VERSION "$Format:%h$"

NS_ :

BS_:

BU_: LOGGER SAMPLE

BO_ 256 SAMPLE_A_alertLog: 8 SAMPLE_A
 SG_ SAMPLE_A_alertID M : 0|7@1+ (1,0) [0|76] "" LOGGER
 SG_ SAMPLE_A_alertState : 15|1@1+ (1,0) [0|1] "" LOGGER
 SG_ SAMPLE_A_a005_data1 m5 : 16|1@1+ (1,0) [0|1] "" LOGGER
 SG_ SAMPLE_A_a005_data2 m5 : 17|1@1+ (1,0) [0|1] "" LOGGER
 SG_ SAMPLE_A_a006_data1 m6 : 16|16@1+ (1,0) [0|65535] "" LOGGER
 SG_ SAMPLE_A_a006_data2 m6 : 32|16@1+ (1,0) [0|65535] "" LOGGER
 SG_ SAMPLE_A_a008_data1 m8 : 16|16@1+ (1,0) [0|65535] "" LOGGER
 SG_ SAMPLE_A_a008_data2 m8 : 32|8@1+ (1,0) [0|255] "" LOGGER
 SG_ SAMPLE_A_a008_data3 m8 : 40|8@1+ (1,0) [0|255] "" LOGGER
 SG_ SAMPLE_A_a008_data4 m8 : 48|1@1+ (1,0) [0|1] "" LOGGER
 SG_ SAMPLE_A_a008_data5 m8 : 49|1@1+ (1,0) [0|1] "" LOGGER
 SG_ SAMPLE_A_a009_data1 m9 : 16|16@1+ (1,0) [0|65535] "" LOGGER
 SG_ SAMPLE_A_a009_data2 m9 : 32|8@1+ (1,0) [0|255] "" LOGGER
 SG_ SAMPLE_A_a009_data3 m9 : 40|8@1+ (1,0) [0|255] "" LOGGER
 SG_ SAMPLE_A_a009_data4 m9 : 48|1@1+ (1,0) [0|1] "" LOGGER
 SG_ SAMPLE_A_a009_data5 m9 : 49|1@1+ (1,0) [0|1] "" LOGGER
 SG_ SAMPLE_A_a020_data1 m20 : 16|7@1+ (1,1) [1|128] "" LOGGER
 SG_ SAMPLE_A_a020_data2 m20 : 24|8@1+ (0.5,0) [0|100] "PCT" LOGGER
 SG_ SAMPLE_A_a020_data3 m20 : 32|7@1+ (1,1) [1|128] "" LOGGER
 SG_ SAMPLE_A_a020_data4 m20 : 40|8@1+ (0.5,0) [0|100] "PCT" LOGGER
 SG_ SAMPLE_A_a020_data5 m20 : 48|8@1+ (0.5,0) [0|100] "PCT" LOGGER
 SG_ SAMPLE_A_a021_data1 m21 : 16|7@1+ (1,1) [1|128] "" LOGGER
 SG_ SAMPLE_A_a021_data2 m21 : 24|8@1+ (0.5,0) [0|100] "PCT" LOGGER
 SG_ SAMPLE_A_a021_data3 m21 : 32|7@1+ (1,1) [1|128] "" LOGGER
 SG_ SAMPLE_A_a021_data4 m21 : 40|8@1+ (0.5,0) [0|100] "PCT" LOGGER
 SG_ SAMPLE_A_a021_data5 m21 : 48|7@1+ (1,0) [0|100] "PCT" LOGGER
 SG_ SAMPLE_A_a021_data6 m21 : 56|7@1+ (1,0) [0|100] "PCT" LOGGER

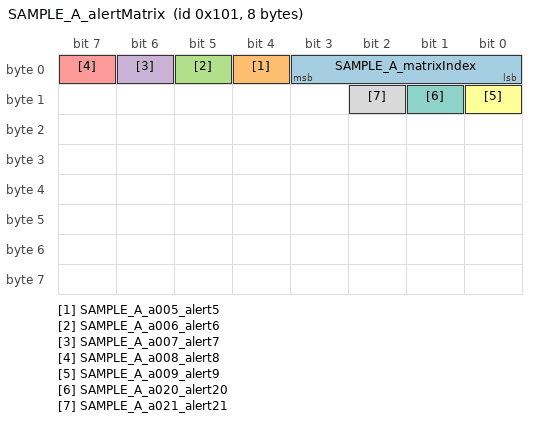
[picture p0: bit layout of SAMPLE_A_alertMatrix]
BO_ 257 SAMPLE_A_alertMatrix: 8 SAMPLE_A
 SG_ SAMPLE_A_matrixIndex : 0|4@1+ (1,0) [0|15] "" Vector__XXX
 SG_ SAMPLE_A_a005_alert5 : 4|1@1+ (1,0) [0|1] "" LOGGER
 SG_ SAMPLE_A_a006_alert6 : 5|1@1+ (1,0) [0|1] "" LOGGER
 SG_ SAMPLE_A_a007_alert7 : 6|1@1+ (1,0) [0|1] "" LOGGER
 SG_ SAMPLE_A_a008_alert8 : 7|1@1+ (1,0) [0|1] "" LOGGER
 SG_ SAMPLE_A_a009_alert9 : 8|1@1+ (1,0) [0|1] "" LOGGER
 SG_ SAMPLE_A_a020_alert20 : 9|1@1+ (1,0) [0|1] "" LOGGER
 SG_ SAMPLE_A_a021_alert21 : 10|1@1+ (1,0) [0|1] "" LOGGER

BO_ 1792 SAMPLE_B_debug: 8 SAMPLE_B
 SG_ SAMPLE_B_debugMultiplexer M : 0|8@1+ (1,0) [0|9] "" Vector__XXX
 SG_ SAMPLE_B_m0_data1 m0 : 8|10@1+ (0.1,0) [0|100] "%" Vector__XXX
 SG_ SAMPLE_B_m0_data2 m0 : 18|10@1+ (0.1,0) [0|100] "%" Vector__XXX
 SG_ SAMPLE_B_m0_data3 m0 : 28|10@1+ (0.1,0) [0|100] "%" Vector__XXX
 SG_ SAMPLE_B_m0_data4 m0 : 38|10@1+ (0.002,0) [0|2] "A" Vector__XXX
 SG_ SAMPLE_B_m0_data5 m0 : 48|6@1+ (0.025,0) [0|1.55] "A" Vector__XXX
 SG_ SAMPLE_B_m0_data6 m0 : 54|1@1+ (1,0) [0|1] "" Vector__XXX
 SG_ SAMPLE_B_m0_data7 m0 : 55|1@1+ (1,0) [0|1] "" Vector__XXX
 SG_ SAMPLE_B_m0_data8 m0 : 56|1@1+ (1,0) [0|1] "" Vector__XXX
 SG_ SAMPLE_B_m0_data9 m0 : 57|1@1+ (1,0) [0|1] "" Vector__XXX
 SG_ SAMPLE_B_m0_data10 m0 : 58|1@1+ (1,0) [0|1] "" Vector__XXX
 SG_ SAMPLE_B_m0_data11 m0 : 59|1@1+ (1,0) [0|1] "" Vector__XXX
 SG_ SAMPLE_B_m0_data12 m0 : 60|1@1+ (1,0) [0|1] "" Vector__XXX
 SG_ SAMPLE_B_m0_data13 m0 : 61|1@1+ (1,0) [0|1] "" Vector__XXX
 SG_ SAMPLE_B_m0_data14 m0 : 62|1@1+ (1,0) [0|1] "" Vector__XXX
 SG_ SAMPLE_B_m1_data1 m1 : 8|12@1+ (0.005,0) [0|20.47] "Ah" Vector__XXX
 SG_ SAMPLE_B_m1_data2 m1 : 20|12@1+ (0.005,0) [0|20.47] "Ah" Vector__XXX
 SG_ SAMPLE_B_m1_data3 m1 : 32|5@1+ (1,1) [1|31] "" Vector__XXX
 SG_ SAMPLE_B_m1_data4 m1 : 40|5@1+ (1,1) [1|31] "" Vector__XXX
 SG_ SAMPLE_B_m1_data5 m1 : 48|12@1+ (0.02,0) [0|81.88] "V" Vector__XXX
 SG_ SAMPLE_B_m2_data1 m2 : 8|11@1+ (0.1,-50) [-50|154.6] "C" Vector__XXX
 SG_ SAMPLE_B_m2_data2 m2 : 19|11@1+ (0.1,-50) [-50|154.6] "C" Vector__XXX
 SG_ SAMPLE_B_m2_data3 m2 : 30|11@1+ (0.1,-50) [-50|154.6] "C" Vector__XXX
 SG_ SAMPLE_B_m2_data4 m2 : 41|11@1+ (0.1,-50) [-50|154.6] "C" Vector__XXX
 SG_ SAMPLE_B_m2_data5 m2 : 52|12@1+ (0.002,0) [0|8.188] "V" Vector__XXX
 SG_ SAMPLE_B_m3_data1 m3 : 8|5@1+ (1,0) [0|18] "" Vector__XXX
 SG_ SAMPLE_B_m3_data2 m3 : 16|4@1+ (1,0) [0|15] "" Vector__XXX
 SG_ SAMPLE_B_m3_data3 m3 : 20|7@1+ (0.1,90) [90|100] "%" Vector__XXX
 SG_ SAMPLE_B_m3_data4 m3 : 27|10@1+ (0.1,0) [0|80] "%" Vector__XXX
 SG_ SAMPLE_B_m3_data5 m3 : 37|7@1+ (0.2,-0.2) [-0.2|25] "Ah" Vector__XXX
 SG_ SAMPLE_B_m3_data6 m3 : 44|10@1+ (0.2,-0.2) [-0.2|204.2] "Wh" Vector__XXX
 SG_ SAMPLE_B_m3_data7 m3 : 54|10@1+ (0.1,-0.1) [-0.1|102.1] "min" Vector__XXX
 SG_ SAMPLE_B_m4_data1 m4 : 8|12@1+ (0.015,0) [0|61.41] "V" Vector__XXX
 SG_ SAMPLE_B_m4_data2 m4 : 20|10@1+ (0.1,0) [0|100] "%" Vector__XXX
 SG_ SAMPLE_B_m4_data3 m4 : 30|10@1+ (0.1,0) [0|100] "%" Vector__XXX
 SG_ SAMPLE_B_m4_data4 m4 : 40|10@1+ (0.1,0) [0|100] "%" Vector__XXX
 SG_ SAMPLE_B_m4_data5 m4 : 50|12@1- (0.25,0) [-511|511] "A" Vector__XXX
 SG_ SAMPLE_B_m5_data1 m5 : 8|14@1+ (2.5e-5,0) [0|0.4] "Ohm" Vector__XXX
 SG_ SAMPLE_B_m5_data2 m5 : 24|14@1+ (2.5e-5,0) [0|0.4] "Ohm" Vector__XXX
 SG_ SAMPLE_B_m5_data3 m5 : 40|14@1+ (2.5e-5,0) [0|0.4] "Ohm" Vector__XXX
 SG_ SAMPLE_B_m5_data4 m5 : 54|5@1+ (1,1) [1|31] "" Vector__XXX
 SG_ SAMPLE_B_m5_data5 m5 : 59|5@1+ (1,1) [1|31] "" Vector__XXX
 SG_ SAMPLE_B_m6_data1 m6 : 8|12@1+ (2,-8000) [-8000|0] "W" Vector__XXX
 SG_ SAMPLE_B_m6_data2 m6 : 20|12@1+ (2,0) [0|8000] "W" Vector__XXX
 SG_ SAMPLE_B_m6_data3 m6 : 32|10@1+ (0.005,0) [0|5.115] "V" Vector__XXX
 SG_ SAMPLE_B_m6_data4 m6 : 42|10@1+ (0.005,0) [0|5.115] "V" Vector__XXX
 SG_ SAMPLE_B_m6_data5 m6 : 52|12@1+ (1,0) [0|4000] "Wh" Vector__XXX
 SG_ SAMPLE_B_m7_data1 m7 : 8|32@1+ (1,0) [0|4294967295] "s" Vector__XXX
 SG_ SAMPLE_B_m7_data2 m7 : 40|8@1+ (0.01,0.5) [0.5|3.04] "ratio" Vector__XXX
 SG_ SAMPLE_B_m7_data3 m7 : 48|5@1+ (1,1) [1|31] "" Vector__XXX
 SG_ SAMPLE_B_m7_data4 m7 : 56|4@1+ (1,0) [0|15] "" Vector__XXX
 SG_ SAMPLE_B_m8_data1 m8 : 8|13@1+ (864000,0) [0|7077024000] "s" Vector__XXX
 SG_ SAMPLE_B_m8_data2 m8 : 21|9@1+ (0.1,0) [0|51] "%" Vector__XXX
 SG_ SAMPLE_B_m8_data3 m8 : 32|14@1- (0.1,200) [-100|500] "%" Vector__XXX
 SG_ SAMPLE_B_m8_data4 m8 : 46|10@1+ (0.1,0) [0|102.2] "%" Vector__XXX
 SG_ SAMPLE_B_m8_data5 m8 : 56|3@1+ (1,0) [0|4] "" Vector__XXX
 SG_ SAMPLE_B_m9_data1 m9 : 8|8@1+ (0.01,0.5) [0.5|3.04] "ratio" Vector__XXX
 SG_ SAMPLE_B_m9_data2 m9 : 16|8@1+ (0.01,0.5) [0.5|3.04] "ratio" Vector__XXX
 SG_ SAMPLE_B_m9_data3 m9 : 24|12@1- (0.25,0) [-511|511] "A" Vector__XXX
 SG_ SAMPLE_B_m9_data4 m9 : 40|5@1+ (1,1) [1|31] "" Vector__XXX
 SG_ SAMPLE_B_m9_data5 m9 : 48|5@1+ (1,1) [1|31] "" Vector__XXX

BA_DEF_ "Baudrate" INT 0 1000000;
BA_DEF_ "BusID" INT 0 255;
BA_DEF_ "BusType" STRING ;
BA_DEF_ "DBName" STRING ;
BA_DEF_ "NetworkName" STRING ;
BA_DEF_ "NmBaseAddress" HEX 1024 1087;
BA_DEF_ BO_ "GatewayMessageSendType" ENUM "UseGenMsgSendType","onWrite","noAutoCode";
BA_DEF_ BO_ "GenMsgCycleTime" INT 0 0;
BA_DEF_ BO_ "GenMsgILSupport" ENUM "No","Yes";
BA_DEF_ BO_ "GenMsgSendType" ENUM "Cyclic","NotUsed","NotUsed","NotUsed","NotUsed","NotUsed","NotUsed","IfActive","NoMsgSendType","Sporadic";
BA_DEF_ BO_ "MessageIdType" ENUM "normal","udsRequest","udsResponse","udsReserved","udsFunctionalRequest","networkManagement","bootloader","xcp","dtc","diagnostic","vendorExempt";
BA_DEF_ BU_ "NodeLayerModules" STRING ;
BA_DEF_ SG_ "GenSigSendType" ENUM "Cyclic","OnWrite","OnWriteWithRepetition","OnChange","OnChangeWithRepetition","IfActive","IfActiveWithRepetition","NoSigSendType";
BA_DEF_ SG_ "GenSigStartValue" INT 0 0;

BA_DEF_DEF_ "Baudrate" 500000;
BA_DEF_DEF_ "BusID" 0;
BA_DEF_DEF_ "BusType" "CAN";
BA_DEF_DEF_ "DBName" "";
BA_DEF_DEF_ "GatewayMessageSendType" "UseGenMsgSendType";
BA_DEF_DEF_ "GenMsgCycleTime" 0;
BA_DEF_DEF_ "GenMsgILSupport" "Yes";
BA_DEF_DEF_ "GenMsgSendType" "NoMsgSendType";
BA_DEF_DEF_ "GenSigSendType" "Cyclic";
BA_DEF_DEF_ "GenSigStartValue" 0;
BA_DEF_DEF_ "MessageIdType" "normal";
BA_DEF_DEF_ "NetworkName" "";
BA_DEF_DEF_ "NmBaseAddress" 1024;
BA_DEF_DEF_ "NodeLayerModules" "CANoeILNLVector.dll";

BA_ "BusID" 2;
BA_ "DBName" "SAMPLE_Bus";
BA_ "NetworkName" "SAMPLE";
BA_ "GenMsgCycleTime" BO_ 257 1000;
BA_ "GenMsgSendType" BO_ 257 0;
BA_ "GenMsgCycleTime" BO_ 1792 100;
BA_ "GenMsgSendType" BO_ 1792 0;
BA_ "GenSigStartValue" SG_ 1792 SAMPLE_m6_data1 4000;
